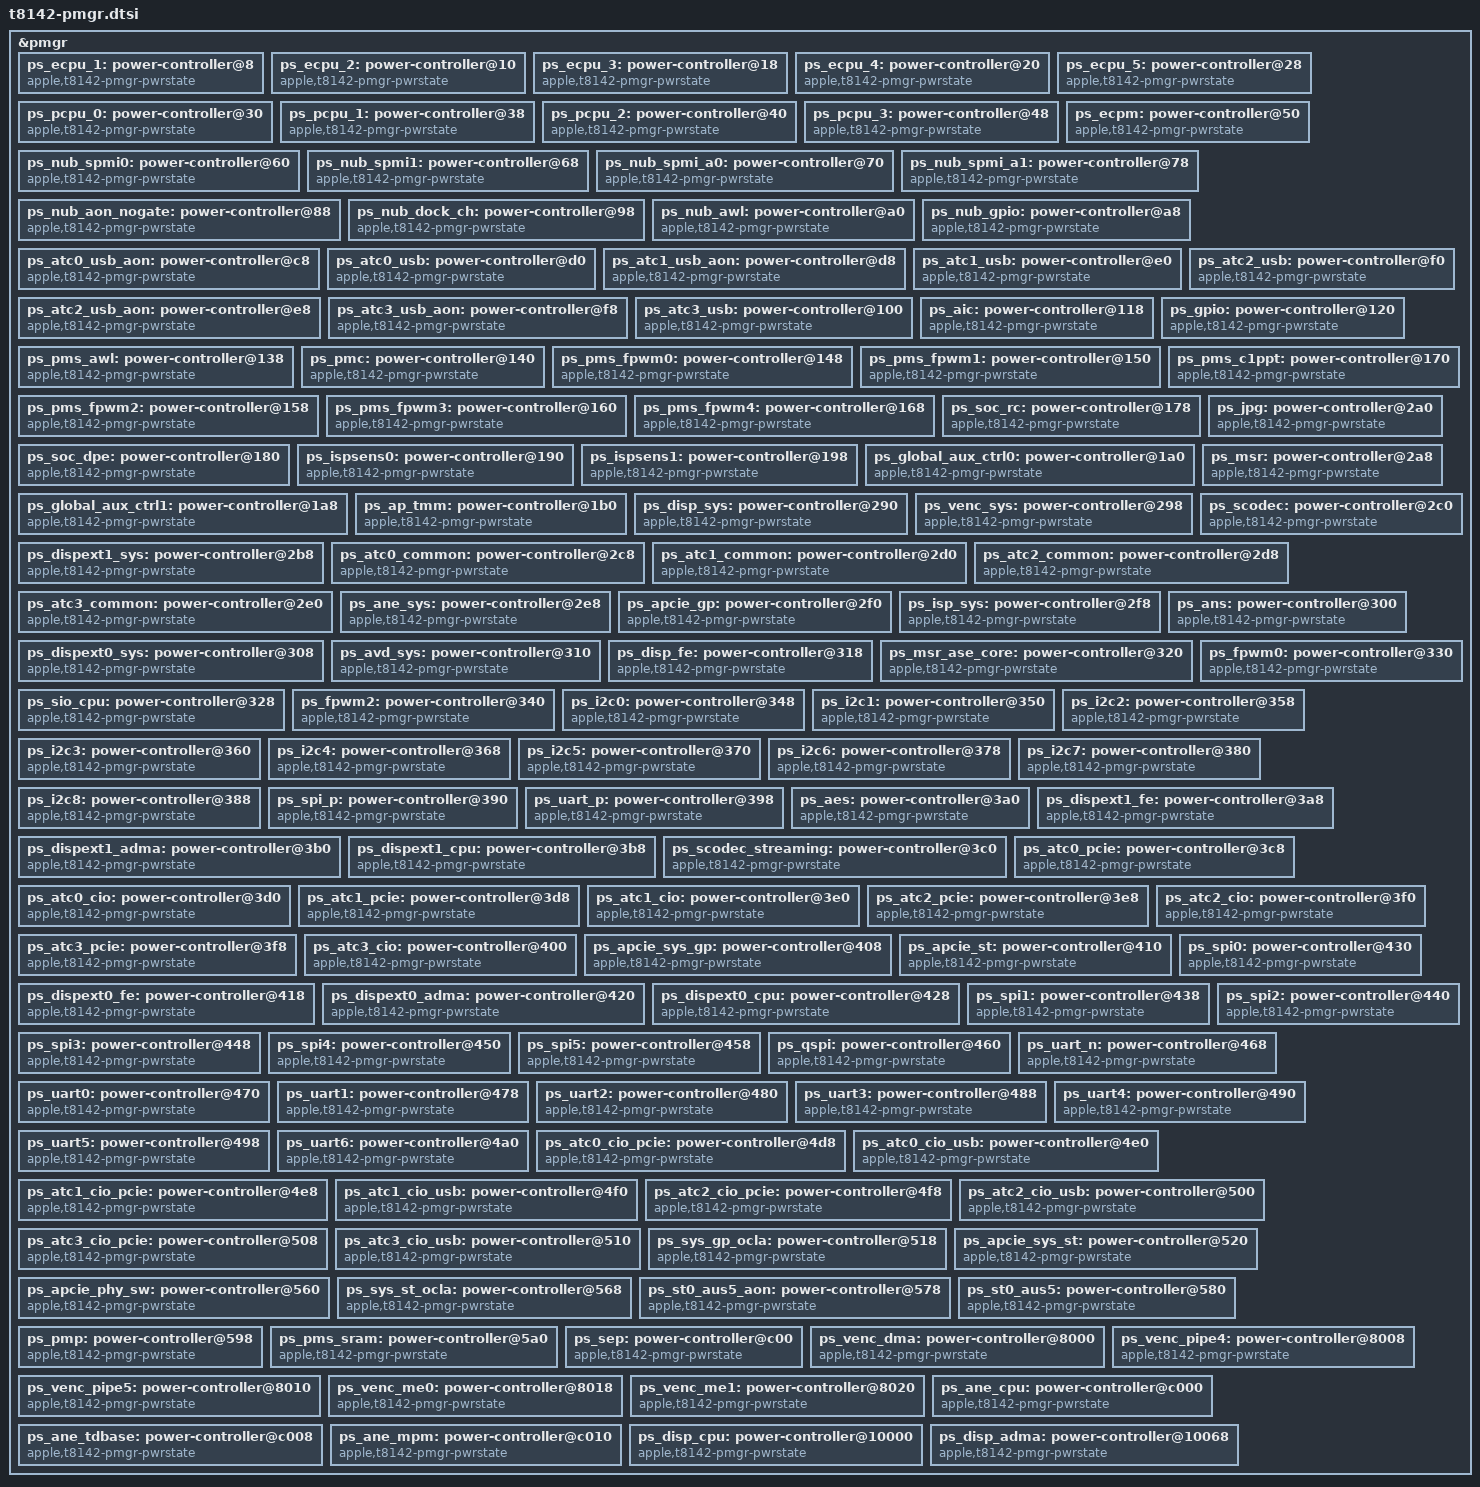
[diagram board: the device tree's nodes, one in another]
// SPDX-License-Identifier: GPL-2.0-or-later
/*
 * PMGR Power domains for the Apple T8142 "M5" SoC — 草稿
 *
 * ⚠️ 本文件是上游对应文件的**衍生作品**,依 GPL 保留署名:
 *     Copyright The Asahi Linux Contributors
 *     上游以 "GPL-2.0+ OR MIT" 发布;本文件选择 GPL-2.0-or-later
 *
 * 由 tools/pmgr_join.py 生成,输入:
 *   模板: t8132-pmgr.dtsi  (sha256 17c4fd5a7ec04af6)
 *       上游 AsahiLinux/linux, arch/arm64/boot/dts/apple/t8132-pmgr.dtsi
 *   数值: 本机 ADT 的 pmgr `devices` 属性(387 条)
 * 生成日期: 2026-10-11
 *
 * ⚠️ 草稿。必须人工校对 + 真机验证。见 docs/PMGR-DELTA.md。
 *
 * 记录 387 条:非虚拟 141 条,其中偏移唯一、写出为节点的 135 条。
 *
 * 地址结构:**绝对地址 = base(group) + offset**
 *   base 由 pmgr 的 ps-groups 表索引 reg 属性得到,本机三组分别是
 *   0x170700000 / 0x178280000 / 0x370e80000。
 *
 * 未写出的(6 条偏移仍不唯一 + 246 条虚拟域)见文件末尾两个注释块。
 */

/*
 * 🚨 本文件的 `reg` 是 pmgr **块内偏移**(来自 devices 的 offset 字段),
 *    配合 ps-groups 的 base 才构成绝对地址 —— 见 docs/PMGR-DEVICES.md。
 *    ⚠️ 且 pmgr 节点本身的地址在 t8142.dtsi 里是未翻译的子地址,注意。
 */

&pmgr {

	/* ⚠️ M4 模板里没有同名项 —— 下面属性是猜的,需确认 */
	ps_ecpu_1: power-controller@8 {
		compatible = "apple,t8142-pmgr-pwrstate", "apple,t8103-pmgr-pwrstate";
		reg = <0x8 4>;
		#power-domain-cells = <0>;
		#reset-cells = <0>;
		label = "ecpu_1";
	};

	/* ⚠️ M4 模板里没有同名项 —— 下面属性是猜的,需确认 */
	ps_ecpu_2: power-controller@10 {
		compatible = "apple,t8142-pmgr-pwrstate", "apple,t8103-pmgr-pwrstate";
		reg = <0x10 4>;
		#power-domain-cells = <0>;
		#reset-cells = <0>;
		label = "ecpu_2";
	};

	/* ⚠️ M4 模板里没有同名项 —— 下面属性是猜的,需确认 */
	ps_ecpu_3: power-controller@18 {
		compatible = "apple,t8142-pmgr-pwrstate", "apple,t8103-pmgr-pwrstate";
		reg = <0x18 4>;
		#power-domain-cells = <0>;
		#reset-cells = <0>;
		label = "ecpu_3";
	};

	/* ⚠️ M4 模板里没有同名项 —— 下面属性是猜的,需确认 */
	ps_ecpu_4: power-controller@20 {
		compatible = "apple,t8142-pmgr-pwrstate", "apple,t8103-pmgr-pwrstate";
		reg = <0x20 4>;
		#power-domain-cells = <0>;
		#reset-cells = <0>;
		label = "ecpu_4";
	};

	/* ⚠️ M4 模板里没有同名项 —— 下面属性是猜的,需确认 */
	ps_ecpu_5: power-controller@28 {
		compatible = "apple,t8142-pmgr-pwrstate", "apple,t8103-pmgr-pwrstate";
		reg = <0x28 4>;
		#power-domain-cells = <0>;
		#reset-cells = <0>;
		label = "ecpu_5";
	};

	/* ⚠️ M4 模板里没有同名项 —— 下面属性是猜的,需确认 */
	ps_pcpu_0: power-controller@30 {
		compatible = "apple,t8142-pmgr-pwrstate", "apple,t8103-pmgr-pwrstate";
		reg = <0x30 4>;
		#power-domain-cells = <0>;
		#reset-cells = <0>;
		label = "pcpu_0";
	};

	/* ⚠️ M4 模板里没有同名项 —— 下面属性是猜的,需确认 */
	ps_pcpu_1: power-controller@38 {
		compatible = "apple,t8142-pmgr-pwrstate", "apple,t8103-pmgr-pwrstate";
		reg = <0x38 4>;
		#power-domain-cells = <0>;
		#reset-cells = <0>;
		label = "pcpu_1";
	};

	/* ⚠️ M4 模板里没有同名项 —— 下面属性是猜的,需确认 */
	ps_pcpu_2: power-controller@40 {
		compatible = "apple,t8142-pmgr-pwrstate", "apple,t8103-pmgr-pwrstate";
		reg = <0x40 4>;
		#power-domain-cells = <0>;
		#reset-cells = <0>;
		label = "pcpu_2";
	};

	/* ⚠️ M4 模板里没有同名项 —— 下面属性是猜的,需确认 */
	ps_pcpu_3: power-controller@48 {
		compatible = "apple,t8142-pmgr-pwrstate", "apple,t8103-pmgr-pwrstate";
		reg = <0x48 4>;
		#power-domain-cells = <0>;
		#reset-cells = <0>;
		label = "pcpu_3";
	};

	/* ⚠️ M4 模板里没有同名项 —— 下面属性是猜的,需确认 */
	ps_ecpm: power-controller@50 {
		compatible = "apple,t8142-pmgr-pwrstate", "apple,t8103-pmgr-pwrstate";
		reg = <0x50 4>;
		#power-domain-cells = <0>;
		#reset-cells = <0>;
		label = "ecpm";
	};

	ps_nub_spmi0: power-controller@60 {
		compatible = "apple,t8142-pmgr-pwrstate", "apple,t8103-pmgr-pwrstate";
		reg = <0x60 4>;
		#power-domain-cells = <0>;
		#reset-cells = <0>;
		label = "nub_spmi0";  /* 结构抄自 M4 模板同名项 */
		apple,always-on; /* Core device */
	};

	ps_nub_spmi1: power-controller@68 {
		compatible = "apple,t8142-pmgr-pwrstate", "apple,t8103-pmgr-pwrstate";
		reg = <0x68 4>;
		#power-domain-cells = <0>;
		#reset-cells = <0>;
		label = "nub_spmi1";  /* 结构抄自 M4 模板同名项 */
		apple,always-on; /* Core device */
	};

	ps_nub_spmi_a0: power-controller@70 {
		compatible = "apple,t8142-pmgr-pwrstate", "apple,t8103-pmgr-pwrstate";
		reg = <0x70 4>;
		#power-domain-cells = <0>;
		#reset-cells = <0>;
		label = "nub_spmi_a0";  /* 结构抄自 M4 模板同名项 */
		apple,always-on; /* Core device */
	};

	ps_nub_spmi_a1: power-controller@78 {
		compatible = "apple,t8142-pmgr-pwrstate", "apple,t8103-pmgr-pwrstate";
		reg = <0x78 4>;
		#power-domain-cells = <0>;
		#reset-cells = <0>;
		label = "nub_spmi_a1";  /* 结构抄自 M4 模板同名项 */
		apple,always-on; /* Core device */
	};

	/* ⚠️ M4 模板里没有同名项 —— 下面属性是猜的,需确认 */
	ps_nub_aon_nogate: power-controller@88 {
		compatible = "apple,t8142-pmgr-pwrstate", "apple,t8103-pmgr-pwrstate";
		reg = <0x88 4>;
		#power-domain-cells = <0>;
		#reset-cells = <0>;
		label = "nub_aon_nogate";
	};

	/* ⚠️ M4 模板里没有同名项 —— 下面属性是猜的,需确认 */
	ps_nub_dock_ch: power-controller@98 {
		compatible = "apple,t8142-pmgr-pwrstate", "apple,t8103-pmgr-pwrstate";
		reg = <0x98 4>;
		#power-domain-cells = <0>;
		#reset-cells = <0>;
		label = "nub_dock_ch";
	};

	/* ⚠️ M4 模板里没有同名项 —— 下面属性是猜的,需确认 */
	ps_nub_awl: power-controller@a0 {
		compatible = "apple,t8142-pmgr-pwrstate", "apple,t8103-pmgr-pwrstate";
		reg = <0xa0 4>;
		#power-domain-cells = <0>;
		#reset-cells = <0>;
		label = "nub_awl";
	};

	ps_nub_gpio: power-controller@a8 {
		compatible = "apple,t8142-pmgr-pwrstate", "apple,t8103-pmgr-pwrstate";
		reg = <0xa8 4>;
		#power-domain-cells = <0>;
		#reset-cells = <0>;
		label = "nub_gpio";  /* 结构抄自 M4 模板同名项 */
		apple,always-on; /* Core device */
	};

	ps_atc0_usb_aon: power-controller@c8 {
		compatible = "apple,t8142-pmgr-pwrstate", "apple,t8103-pmgr-pwrstate";
		reg = <0xc8 4>;
		#power-domain-cells = <0>;
		#reset-cells = <0>;
		label = "atc0_usb_aon";  /* 结构抄自 M4 模板同名项 */
	};

	ps_atc0_usb: power-controller@d0 {
		compatible = "apple,t8142-pmgr-pwrstate", "apple,t8103-pmgr-pwrstate";
		reg = <0xd0 4>;
		#power-domain-cells = <0>;
		#reset-cells = <0>;
		label = "atc0_usb";  /* 结构抄自 M4 模板同名项 */
	};

	ps_atc1_usb_aon: power-controller@d8 {
		compatible = "apple,t8142-pmgr-pwrstate", "apple,t8103-pmgr-pwrstate";
		reg = <0xd8 4>;
		#power-domain-cells = <0>;
		#reset-cells = <0>;
		label = "atc1_usb_aon";  /* 结构抄自 M4 模板同名项 */
	};

	ps_atc1_usb: power-controller@e0 {
		compatible = "apple,t8142-pmgr-pwrstate", "apple,t8103-pmgr-pwrstate";
		reg = <0xe0 4>;
		#power-domain-cells = <0>;
		#reset-cells = <0>;
		label = "atc1_usb";  /* 结构抄自 M4 模板同名项 */
	};

	ps_atc2_usb_aon: power-controller@e8 {
		compatible = "apple,t8142-pmgr-pwrstate", "apple,t8103-pmgr-pwrstate";
		reg = <0xe8 4>;
		#power-domain-cells = <0>;
		#reset-cells = <0>;
		label = "atc2_usb_aon";  /* 结构抄自 M4 模板同名项 */
	};

	ps_atc2_usb: power-controller@f0 {
		compatible = "apple,t8142-pmgr-pwrstate", "apple,t8103-pmgr-pwrstate";
		reg = <0xf0 4>;
		#power-domain-cells = <0>;
		#reset-cells = <0>;
		label = "atc2_usb";  /* 结构抄自 M4 模板同名项 */
	};

	ps_atc3_usb_aon: power-controller@f8 {
		compatible = "apple,t8142-pmgr-pwrstate", "apple,t8103-pmgr-pwrstate";
		reg = <0xf8 4>;
		#power-domain-cells = <0>;
		#reset-cells = <0>;
		label = "atc3_usb_aon";  /* 结构抄自 M4 模板同名项 */
	};

	ps_atc3_usb: power-controller@100 {
		compatible = "apple,t8142-pmgr-pwrstate", "apple,t8103-pmgr-pwrstate";
		reg = <0x100 4>;
		#power-domain-cells = <0>;
		#reset-cells = <0>;
		label = "atc3_usb";  /* 结构抄自 M4 模板同名项 */
	};

	ps_aic: power-controller@118 {
		compatible = "apple,t8142-pmgr-pwrstate", "apple,t8103-pmgr-pwrstate";
		reg = <0x118 4>;
		#power-domain-cells = <0>;
		#reset-cells = <0>;
		label = "aic";  /* 结构抄自 M4 模板同名项 */
		apple,always-on; /* Core device */
	};

	ps_gpio: power-controller@120 {
		compatible = "apple,t8142-pmgr-pwrstate", "apple,t8103-pmgr-pwrstate";
		reg = <0x120 4>;
		#power-domain-cells = <0>;
		#reset-cells = <0>;
		label = "gpio";  /* 结构抄自 M4 模板同名项 */
	};

	/* ⚠️ M4 模板里没有同名项 —— 下面属性是猜的,需确认 */
	ps_pms_awl: power-controller@138 {
		compatible = "apple,t8142-pmgr-pwrstate", "apple,t8103-pmgr-pwrstate";
		reg = <0x138 4>;
		#power-domain-cells = <0>;
		#reset-cells = <0>;
		label = "pms_awl";
	};

	ps_pmc: power-controller@140 {
		compatible = "apple,t8142-pmgr-pwrstate", "apple,t8103-pmgr-pwrstate";
		reg = <0x140 4>;
		#power-domain-cells = <0>;
		#reset-cells = <0>;
		label = "pmc";  /* 结构抄自 M4 模板同名项 */
	};

	ps_pms_fpwm0: power-controller@148 {
		compatible = "apple,t8142-pmgr-pwrstate", "apple,t8103-pmgr-pwrstate";
		reg = <0x148 4>;
		#power-domain-cells = <0>;
		#reset-cells = <0>;
		label = "pms_fpwm0";  /* 结构抄自 M4 模板同名项 */
	};

	ps_pms_fpwm1: power-controller@150 {
		compatible = "apple,t8142-pmgr-pwrstate", "apple,t8103-pmgr-pwrstate";
		reg = <0x150 4>;
		#power-domain-cells = <0>;
		#reset-cells = <0>;
		label = "pms_fpwm1";  /* 结构抄自 M4 模板同名项 */
	};

	ps_pms_fpwm2: power-controller@158 {
		compatible = "apple,t8142-pmgr-pwrstate", "apple,t8103-pmgr-pwrstate";
		reg = <0x158 4>;
		#power-domain-cells = <0>;
		#reset-cells = <0>;
		label = "pms_fpwm2";  /* 结构抄自 M4 模板同名项 */
	};

	ps_pms_fpwm3: power-controller@160 {
		compatible = "apple,t8142-pmgr-pwrstate", "apple,t8103-pmgr-pwrstate";
		reg = <0x160 4>;
		#power-domain-cells = <0>;
		#reset-cells = <0>;
		label = "pms_fpwm3";  /* 结构抄自 M4 模板同名项 */
	};

	ps_pms_fpwm4: power-controller@168 {
		compatible = "apple,t8142-pmgr-pwrstate", "apple,t8103-pmgr-pwrstate";
		reg = <0x168 4>;
		#power-domain-cells = <0>;
		#reset-cells = <0>;
		label = "pms_fpwm4";  /* 结构抄自 M4 模板同名项 */
	};

	ps_pms_c1ppt: power-controller@170 {
		compatible = "apple,t8142-pmgr-pwrstate", "apple,t8103-pmgr-pwrstate";
		reg = <0x170 4>;
		#power-domain-cells = <0>;
		#reset-cells = <0>;
		label = "pms_c1ppt";  /* 结构抄自 M4 模板同名项 */
	};

	ps_soc_rc: power-controller@178 {
		compatible = "apple,t8142-pmgr-pwrstate", "apple,t8103-pmgr-pwrstate";
		reg = <0x178 4>;
		#power-domain-cells = <0>;
		#reset-cells = <0>;
		label = "soc_rc";  /* 结构抄自 M4 模板同名项 */
	};

	ps_soc_dpe: power-controller@180 {
		compatible = "apple,t8142-pmgr-pwrstate", "apple,t8103-pmgr-pwrstate";
		reg = <0x180 4>;
		#power-domain-cells = <0>;
		#reset-cells = <0>;
		label = "soc_dpe";  /* 结构抄自 M4 模板同名项 */
		apple,always-on; /* Core device */
	};

	/* ⚠️ M4 模板里没有同名项 —— 下面属性是猜的,需确认 */
	ps_ispsens0: power-controller@190 {
		compatible = "apple,t8142-pmgr-pwrstate", "apple,t8103-pmgr-pwrstate";
		reg = <0x190 4>;
		#power-domain-cells = <0>;
		#reset-cells = <0>;
		label = "ispsens0";
	};

	/* ⚠️ M4 模板里没有同名项 —— 下面属性是猜的,需确认 */
	ps_ispsens1: power-controller@198 {
		compatible = "apple,t8142-pmgr-pwrstate", "apple,t8103-pmgr-pwrstate";
		reg = <0x198 4>;
		#power-domain-cells = <0>;
		#reset-cells = <0>;
		label = "ispsens1";
	};

	/* ⚠️ M4 模板里没有同名项 —— 下面属性是猜的,需确认 */
	ps_global_aux_ctrl0: power-controller@1a0 {
		compatible = "apple,t8142-pmgr-pwrstate", "apple,t8103-pmgr-pwrstate";
		reg = <0x1a0 4>;
		#power-domain-cells = <0>;
		#reset-cells = <0>;
		label = "global_aux_ctrl0";
	};

	/* ⚠️ M4 模板里没有同名项 —— 下面属性是猜的,需确认 */
	ps_global_aux_ctrl1: power-controller@1a8 {
		compatible = "apple,t8142-pmgr-pwrstate", "apple,t8103-pmgr-pwrstate";
		reg = <0x1a8 4>;
		#power-domain-cells = <0>;
		#reset-cells = <0>;
		label = "global_aux_ctrl1";
	};

	ps_ap_tmm: power-controller@1b0 {
		compatible = "apple,t8142-pmgr-pwrstate", "apple,t8103-pmgr-pwrstate";
		reg = <0x1b0 4>;
		#power-domain-cells = <0>;
		#reset-cells = <0>;
		label = "ap_tmm";  /* 结构抄自 M4 模板同名项 */
	};

	ps_disp_sys: power-controller@290 {
		compatible = "apple,t8142-pmgr-pwrstate", "apple,t8103-pmgr-pwrstate";
		reg = <0x290 4>;
		#power-domain-cells = <0>;
		#reset-cells = <0>;
		label = "disp_sys";  /* 结构抄自 M4 模板同名项 */
		apple,always-on; /* Core device */
	};

	ps_venc_sys: power-controller@298 {
		compatible = "apple,t8142-pmgr-pwrstate", "apple,t8103-pmgr-pwrstate";
		reg = <0x298 4>;
		#power-domain-cells = <0>;
		#reset-cells = <0>;
		label = "venc_sys";  /* 结构抄自 M4 模板同名项 */
	};

	ps_jpg: power-controller@2a0 {
		compatible = "apple,t8142-pmgr-pwrstate", "apple,t8103-pmgr-pwrstate";
		reg = <0x2a0 4>;
		#power-domain-cells = <0>;
		#reset-cells = <0>;
		label = "jpg";  /* 结构抄自 M4 模板同名项 */
	};

	ps_msr: power-controller@2a8 {
		compatible = "apple,t8142-pmgr-pwrstate", "apple,t8103-pmgr-pwrstate";
		reg = <0x2a8 4>;
		#power-domain-cells = <0>;
		#reset-cells = <0>;
		label = "msr";  /* 结构抄自 M4 模板同名项 */
	};

	ps_dispext1_sys: power-controller@2b8 {
		compatible = "apple,t8142-pmgr-pwrstate", "apple,t8103-pmgr-pwrstate";
		reg = <0x2b8 4>;
		#power-domain-cells = <0>;
		#reset-cells = <0>;
		label = "dispext1_sys";  /* 结构抄自 M4 模板同名项 */
	};

	ps_scodec: power-controller@2c0 {
		compatible = "apple,t8142-pmgr-pwrstate", "apple,t8103-pmgr-pwrstate";
		reg = <0x2c0 4>;
		#power-domain-cells = <0>;
		#reset-cells = <0>;
		label = "scodec";  /* 结构抄自 M4 模板同名项 */
	};

	ps_atc0_common: power-controller@2c8 {
		compatible = "apple,t8142-pmgr-pwrstate", "apple,t8103-pmgr-pwrstate";
		reg = <0x2c8 4>;
		#power-domain-cells = <0>;
		#reset-cells = <0>;
		label = "atc0_common";  /* 结构抄自 M4 模板同名项 */
	};

	ps_atc1_common: power-controller@2d0 {
		compatible = "apple,t8142-pmgr-pwrstate", "apple,t8103-pmgr-pwrstate";
		reg = <0x2d0 4>;
		#power-domain-cells = <0>;
		#reset-cells = <0>;
		label = "atc1_common";  /* 结构抄自 M4 模板同名项 */
	};

	ps_atc2_common: power-controller@2d8 {
		compatible = "apple,t8142-pmgr-pwrstate", "apple,t8103-pmgr-pwrstate";
		reg = <0x2d8 4>;
		#power-domain-cells = <0>;
		#reset-cells = <0>;
		label = "atc2_common";  /* 结构抄自 M4 模板同名项 */
	};

	ps_atc3_common: power-controller@2e0 {
		compatible = "apple,t8142-pmgr-pwrstate", "apple,t8103-pmgr-pwrstate";
		reg = <0x2e0 4>;
		#power-domain-cells = <0>;
		#reset-cells = <0>;
		label = "atc3_common";  /* 结构抄自 M4 模板同名项 */
	};

	ps_ane_sys: power-controller@2e8 {
		compatible = "apple,t8142-pmgr-pwrstate", "apple,t8103-pmgr-pwrstate";
		reg = <0x2e8 4>;
		#power-domain-cells = <0>;
		#reset-cells = <0>;
		label = "ane_sys";  /* 结构抄自 M4 模板同名项 */
	};

	ps_apcie_gp: power-controller@2f0 {
		compatible = "apple,t8142-pmgr-pwrstate", "apple,t8103-pmgr-pwrstate";
		reg = <0x2f0 4>;
		#power-domain-cells = <0>;
		#reset-cells = <0>;
		label = "apcie_gp";  /* 结构抄自 M4 模板同名项 */
	};

	/* ⚠️ M4 模板里没有同名项 —— 下面属性是猜的,需确认 */
	ps_isp_sys: power-controller@2f8 {
		compatible = "apple,t8142-pmgr-pwrstate", "apple,t8103-pmgr-pwrstate";
		reg = <0x2f8 4>;
		#power-domain-cells = <0>;
		#reset-cells = <0>;
		label = "isp_sys";
	};

	ps_ans: power-controller@300 {
		compatible = "apple,t8142-pmgr-pwrstate", "apple,t8103-pmgr-pwrstate";
		reg = <0x300 4>;
		#power-domain-cells = <0>;
		#reset-cells = <0>;
		label = "ans";  /* 结构抄自 M4 模板同名项 */
	};

	ps_dispext0_sys: power-controller@308 {
		compatible = "apple,t8142-pmgr-pwrstate", "apple,t8103-pmgr-pwrstate";
		reg = <0x308 4>;
		#power-domain-cells = <0>;
		#reset-cells = <0>;
		label = "dispext0_sys";  /* 结构抄自 M4 模板同名项 */
	};

	ps_avd_sys: power-controller@310 {
		compatible = "apple,t8142-pmgr-pwrstate", "apple,t8103-pmgr-pwrstate";
		reg = <0x310 4>;
		#power-domain-cells = <0>;
		#reset-cells = <0>;
		label = "avd_sys";  /* 结构抄自 M4 模板同名项 */
	};

	ps_disp_fe: power-controller@318 {
		compatible = "apple,t8142-pmgr-pwrstate", "apple,t8103-pmgr-pwrstate";
		reg = <0x318 4>;
		#power-domain-cells = <0>;
		#reset-cells = <0>;
		label = "disp_fe";  /* 结构抄自 M4 模板同名项 */
		apple,always-on; /* Core device */
	};

	ps_msr_ase_core: power-controller@320 {
		compatible = "apple,t8142-pmgr-pwrstate", "apple,t8103-pmgr-pwrstate";
		reg = <0x320 4>;
		#power-domain-cells = <0>;
		#reset-cells = <0>;
		label = "msr_ase_core";  /* 结构抄自 M4 模板同名项 */
	};

	ps_sio_cpu: power-controller@328 {
		compatible = "apple,t8142-pmgr-pwrstate", "apple,t8103-pmgr-pwrstate";
		reg = <0x328 4>;
		#power-domain-cells = <0>;
		#reset-cells = <0>;
		label = "sio_cpu";  /* 结构抄自 M4 模板同名项 */
	};

	ps_fpwm0: power-controller@330 {
		compatible = "apple,t8142-pmgr-pwrstate", "apple,t8103-pmgr-pwrstate";
		reg = <0x330 4>;
		#power-domain-cells = <0>;
		#reset-cells = <0>;
		label = "fpwm0";  /* 结构抄自 M4 模板同名项 */
	};

	ps_fpwm2: power-controller@340 {
		compatible = "apple,t8142-pmgr-pwrstate", "apple,t8103-pmgr-pwrstate";
		reg = <0x340 4>;
		#power-domain-cells = <0>;
		#reset-cells = <0>;
		label = "fpwm2";  /* 结构抄自 M4 模板同名项 */
	};

	ps_i2c0: power-controller@348 {
		compatible = "apple,t8142-pmgr-pwrstate", "apple,t8103-pmgr-pwrstate";
		reg = <0x348 4>;
		#power-domain-cells = <0>;
		#reset-cells = <0>;
		label = "i2c0";  /* 结构抄自 M4 模板同名项 */
	};

	ps_i2c1: power-controller@350 {
		compatible = "apple,t8142-pmgr-pwrstate", "apple,t8103-pmgr-pwrstate";
		reg = <0x350 4>;
		#power-domain-cells = <0>;
		#reset-cells = <0>;
		label = "i2c1";  /* 结构抄自 M4 模板同名项 */
	};

	ps_i2c2: power-controller@358 {
		compatible = "apple,t8142-pmgr-pwrstate", "apple,t8103-pmgr-pwrstate";
		reg = <0x358 4>;
		#power-domain-cells = <0>;
		#reset-cells = <0>;
		label = "i2c2";  /* 结构抄自 M4 模板同名项 */
	};

	ps_i2c3: power-controller@360 {
		compatible = "apple,t8142-pmgr-pwrstate", "apple,t8103-pmgr-pwrstate";
		reg = <0x360 4>;
		#power-domain-cells = <0>;
		#reset-cells = <0>;
		label = "i2c3";  /* 结构抄自 M4 模板同名项 */
	};

	ps_i2c4: power-controller@368 {
		compatible = "apple,t8142-pmgr-pwrstate", "apple,t8103-pmgr-pwrstate";
		reg = <0x368 4>;
		#power-domain-cells = <0>;
		#reset-cells = <0>;
		label = "i2c4";  /* 结构抄自 M4 模板同名项 */
	};

	ps_i2c5: power-controller@370 {
		compatible = "apple,t8142-pmgr-pwrstate", "apple,t8103-pmgr-pwrstate";
		reg = <0x370 4>;
		#power-domain-cells = <0>;
		#reset-cells = <0>;
		label = "i2c5";  /* 结构抄自 M4 模板同名项 */
	};

	ps_i2c6: power-controller@378 {
		compatible = "apple,t8142-pmgr-pwrstate", "apple,t8103-pmgr-pwrstate";
		reg = <0x378 4>;
		#power-domain-cells = <0>;
		#reset-cells = <0>;
		label = "i2c6";  /* 结构抄自 M4 模板同名项 */
	};

	ps_i2c7: power-controller@380 {
		compatible = "apple,t8142-pmgr-pwrstate", "apple,t8103-pmgr-pwrstate";
		reg = <0x380 4>;
		#power-domain-cells = <0>;
		#reset-cells = <0>;
		label = "i2c7";  /* 结构抄自 M4 模板同名项 */
	};

	ps_i2c8: power-controller@388 {
		compatible = "apple,t8142-pmgr-pwrstate", "apple,t8103-pmgr-pwrstate";
		reg = <0x388 4>;
		#power-domain-cells = <0>;
		#reset-cells = <0>;
		label = "i2c8";  /* 结构抄自 M4 模板同名项 */
	};

	ps_spi_p: power-controller@390 {
		compatible = "apple,t8142-pmgr-pwrstate", "apple,t8103-pmgr-pwrstate";
		reg = <0x390 4>;
		#power-domain-cells = <0>;
		#reset-cells = <0>;
		label = "spi_p";  /* 结构抄自 M4 模板同名项 */
		apple,always-on; /* Core device */
	};

	ps_uart_p: power-controller@398 {
		compatible = "apple,t8142-pmgr-pwrstate", "apple,t8103-pmgr-pwrstate";
		reg = <0x398 4>;
		#power-domain-cells = <0>;
		#reset-cells = <0>;
		label = "uart_p";  /* 结构抄自 M4 模板同名项 */
		apple,always-on; /* Core device */
	};

	ps_aes: power-controller@3a0 {
		compatible = "apple,t8142-pmgr-pwrstate", "apple,t8103-pmgr-pwrstate";
		reg = <0x3a0 4>;
		#power-domain-cells = <0>;
		#reset-cells = <0>;
		label = "aes";  /* 结构抄自 M4 模板同名项 */
	};

	ps_dispext1_fe: power-controller@3a8 {
		compatible = "apple,t8142-pmgr-pwrstate", "apple,t8103-pmgr-pwrstate";
		reg = <0x3a8 4>;
		#power-domain-cells = <0>;
		#reset-cells = <0>;
		label = "dispext1_fe";  /* 结构抄自 M4 模板同名项 */
	};

	/* ⚠️ M4 模板里没有同名项 —— 下面属性是猜的,需确认 */
	ps_dispext1_adma: power-controller@3b0 {
		compatible = "apple,t8142-pmgr-pwrstate", "apple,t8103-pmgr-pwrstate";
		reg = <0x3b0 4>;
		#power-domain-cells = <0>;
		#reset-cells = <0>;
		label = "dispext1_adma";
	};

	ps_dispext1_cpu: power-controller@3b8 {
		compatible = "apple,t8142-pmgr-pwrstate", "apple,t8103-pmgr-pwrstate";
		reg = <0x3b8 4>;
		#power-domain-cells = <0>;
		#reset-cells = <0>;
		label = "dispext1_cpu";  /* 结构抄自 M4 模板同名项 */
	};

	ps_scodec_streaming: power-controller@3c0 {
		compatible = "apple,t8142-pmgr-pwrstate", "apple,t8103-pmgr-pwrstate";
		reg = <0x3c0 4>;
		#power-domain-cells = <0>;
		#reset-cells = <0>;
		label = "scodec_streaming";  /* 结构抄自 M4 模板同名项 */
	};

	ps_atc0_pcie: power-controller@3c8 {
		compatible = "apple,t8142-pmgr-pwrstate", "apple,t8103-pmgr-pwrstate";
		reg = <0x3c8 4>;
		#power-domain-cells = <0>;
		#reset-cells = <0>;
		label = "atc0_pcie";  /* 结构抄自 M4 模板同名项 */
	};

	ps_atc0_cio: power-controller@3d0 {
		compatible = "apple,t8142-pmgr-pwrstate", "apple,t8103-pmgr-pwrstate";
		reg = <0x3d0 4>;
		#power-domain-cells = <0>;
		#reset-cells = <0>;
		label = "atc0_cio";  /* 结构抄自 M4 模板同名项 */
	};

	ps_atc1_pcie: power-controller@3d8 {
		compatible = "apple,t8142-pmgr-pwrstate", "apple,t8103-pmgr-pwrstate";
		reg = <0x3d8 4>;
		#power-domain-cells = <0>;
		#reset-cells = <0>;
		label = "atc1_pcie";  /* 结构抄自 M4 模板同名项 */
	};

	ps_atc1_cio: power-controller@3e0 {
		compatible = "apple,t8142-pmgr-pwrstate", "apple,t8103-pmgr-pwrstate";
		reg = <0x3e0 4>;
		#power-domain-cells = <0>;
		#reset-cells = <0>;
		label = "atc1_cio";  /* 结构抄自 M4 模板同名项 */
	};

	ps_atc2_pcie: power-controller@3e8 {
		compatible = "apple,t8142-pmgr-pwrstate", "apple,t8103-pmgr-pwrstate";
		reg = <0x3e8 4>;
		#power-domain-cells = <0>;
		#reset-cells = <0>;
		label = "atc2_pcie";  /* 结构抄自 M4 模板同名项 */
	};

	ps_atc2_cio: power-controller@3f0 {
		compatible = "apple,t8142-pmgr-pwrstate", "apple,t8103-pmgr-pwrstate";
		reg = <0x3f0 4>;
		#power-domain-cells = <0>;
		#reset-cells = <0>;
		label = "atc2_cio";  /* 结构抄自 M4 模板同名项 */
	};

	ps_atc3_pcie: power-controller@3f8 {
		compatible = "apple,t8142-pmgr-pwrstate", "apple,t8103-pmgr-pwrstate";
		reg = <0x3f8 4>;
		#power-domain-cells = <0>;
		#reset-cells = <0>;
		label = "atc3_pcie";  /* 结构抄自 M4 模板同名项 */
	};

	ps_atc3_cio: power-controller@400 {
		compatible = "apple,t8142-pmgr-pwrstate", "apple,t8103-pmgr-pwrstate";
		reg = <0x400 4>;
		#power-domain-cells = <0>;
		#reset-cells = <0>;
		label = "atc3_cio";  /* 结构抄自 M4 模板同名项 */
	};

	ps_apcie_sys_gp: power-controller@408 {
		compatible = "apple,t8142-pmgr-pwrstate", "apple,t8103-pmgr-pwrstate";
		reg = <0x408 4>;
		#power-domain-cells = <0>;
		#reset-cells = <0>;
		label = "apcie_sys_gp";  /* 结构抄自 M4 模板同名项 */
	};

	ps_apcie_st: power-controller@410 {
		compatible = "apple,t8142-pmgr-pwrstate", "apple,t8103-pmgr-pwrstate";
		reg = <0x410 4>;
		#power-domain-cells = <0>;
		#reset-cells = <0>;
		label = "apcie_st";  /* 结构抄自 M4 模板同名项 */
	};

	ps_dispext0_fe: power-controller@418 {
		compatible = "apple,t8142-pmgr-pwrstate", "apple,t8103-pmgr-pwrstate";
		reg = <0x418 4>;
		#power-domain-cells = <0>;
		#reset-cells = <0>;
		label = "dispext0_fe";  /* 结构抄自 M4 模板同名项 */
	};

	/* ⚠️ M4 模板里没有同名项 —— 下面属性是猜的,需确认 */
	ps_dispext0_adma: power-controller@420 {
		compatible = "apple,t8142-pmgr-pwrstate", "apple,t8103-pmgr-pwrstate";
		reg = <0x420 4>;
		#power-domain-cells = <0>;
		#reset-cells = <0>;
		label = "dispext0_adma";
	};

	ps_dispext0_cpu: power-controller@428 {
		compatible = "apple,t8142-pmgr-pwrstate", "apple,t8103-pmgr-pwrstate";
		reg = <0x428 4>;
		#power-domain-cells = <0>;
		#reset-cells = <0>;
		label = "dispext0_cpu";  /* 结构抄自 M4 模板同名项 */
	};

	ps_spi0: power-controller@430 {
		compatible = "apple,t8142-pmgr-pwrstate", "apple,t8103-pmgr-pwrstate";
		reg = <0x430 4>;
		#power-domain-cells = <0>;
		#reset-cells = <0>;
		label = "spi0";  /* 结构抄自 M4 模板同名项 */
	};

	ps_spi1: power-controller@438 {
		compatible = "apple,t8142-pmgr-pwrstate", "apple,t8103-pmgr-pwrstate";
		reg = <0x438 4>;
		#power-domain-cells = <0>;
		#reset-cells = <0>;
		label = "spi1";  /* 结构抄自 M4 模板同名项 */
	};

	ps_spi2: power-controller@440 {
		compatible = "apple,t8142-pmgr-pwrstate", "apple,t8103-pmgr-pwrstate";
		reg = <0x440 4>;
		#power-domain-cells = <0>;
		#reset-cells = <0>;
		label = "spi2";  /* 结构抄自 M4 模板同名项 */
	};

	ps_spi3: power-controller@448 {
		compatible = "apple,t8142-pmgr-pwrstate", "apple,t8103-pmgr-pwrstate";
		reg = <0x448 4>;
		#power-domain-cells = <0>;
		#reset-cells = <0>;
		label = "spi3";  /* 结构抄自 M4 模板同名项 */
	};

	ps_spi4: power-controller@450 {
		compatible = "apple,t8142-pmgr-pwrstate", "apple,t8103-pmgr-pwrstate";
		reg = <0x450 4>;
		#power-domain-cells = <0>;
		#reset-cells = <0>;
		label = "spi4";  /* 结构抄自 M4 模板同名项 */
	};

	ps_spi5: power-controller@458 {
		compatible = "apple,t8142-pmgr-pwrstate", "apple,t8103-pmgr-pwrstate";
		reg = <0x458 4>;
		#power-domain-cells = <0>;
		#reset-cells = <0>;
		label = "spi5";  /* 结构抄自 M4 模板同名项 */
	};

	ps_qspi: power-controller@460 {
		compatible = "apple,t8142-pmgr-pwrstate", "apple,t8103-pmgr-pwrstate";
		reg = <0x460 4>;
		#power-domain-cells = <0>;
		#reset-cells = <0>;
		label = "qspi";  /* 结构抄自 M4 模板同名项 */
	};

	ps_uart_n: power-controller@468 {
		compatible = "apple,t8142-pmgr-pwrstate", "apple,t8103-pmgr-pwrstate";
		reg = <0x468 4>;
		#power-domain-cells = <0>;
		#reset-cells = <0>;
		label = "uart_n";  /* 结构抄自 M4 模板同名项 */
	};

	ps_uart0: power-controller@470 {
		compatible = "apple,t8142-pmgr-pwrstate", "apple,t8103-pmgr-pwrstate";
		reg = <0x470 4>;
		#power-domain-cells = <0>;
		#reset-cells = <0>;
		label = "uart0";  /* 结构抄自 M4 模板同名项 */
	};

	ps_uart1: power-controller@478 {
		compatible = "apple,t8142-pmgr-pwrstate", "apple,t8103-pmgr-pwrstate";
		reg = <0x478 4>;
		#power-domain-cells = <0>;
		#reset-cells = <0>;
		label = "uart1";  /* 结构抄自 M4 模板同名项 */
	};

	ps_uart2: power-controller@480 {
		compatible = "apple,t8142-pmgr-pwrstate", "apple,t8103-pmgr-pwrstate";
		reg = <0x480 4>;
		#power-domain-cells = <0>;
		#reset-cells = <0>;
		label = "uart2";  /* 结构抄自 M4 模板同名项 */
	};

	ps_uart3: power-controller@488 {
		compatible = "apple,t8142-pmgr-pwrstate", "apple,t8103-pmgr-pwrstate";
		reg = <0x488 4>;
		#power-domain-cells = <0>;
		#reset-cells = <0>;
		label = "uart3";  /* 结构抄自 M4 模板同名项 */
	};

	ps_uart4: power-controller@490 {
		compatible = "apple,t8142-pmgr-pwrstate", "apple,t8103-pmgr-pwrstate";
		reg = <0x490 4>;
		#power-domain-cells = <0>;
		#reset-cells = <0>;
		label = "uart4";  /* 结构抄自 M4 模板同名项 */
	};

	ps_uart5: power-controller@498 {
		compatible = "apple,t8142-pmgr-pwrstate", "apple,t8103-pmgr-pwrstate";
		reg = <0x498 4>;
		#power-domain-cells = <0>;
		#reset-cells = <0>;
		label = "uart5";  /* 结构抄自 M4 模板同名项 */
	};

	ps_uart6: power-controller@4a0 {
		compatible = "apple,t8142-pmgr-pwrstate", "apple,t8103-pmgr-pwrstate";
		reg = <0x4a0 4>;
		#power-domain-cells = <0>;
		#reset-cells = <0>;
		label = "uart6";  /* 结构抄自 M4 模板同名项 */
	};

	ps_atc0_cio_pcie: power-controller@4d8 {
		compatible = "apple,t8142-pmgr-pwrstate", "apple,t8103-pmgr-pwrstate";
		reg = <0x4d8 4>;
		#power-domain-cells = <0>;
		#reset-cells = <0>;
		label = "atc0_cio_pcie";  /* 结构抄自 M4 模板同名项 */
	};

	ps_atc0_cio_usb: power-controller@4e0 {
		compatible = "apple,t8142-pmgr-pwrstate", "apple,t8103-pmgr-pwrstate";
		reg = <0x4e0 4>;
		#power-domain-cells = <0>;
		#reset-cells = <0>;
		label = "atc0_cio_usb";  /* 结构抄自 M4 模板同名项 */
	};

	ps_atc1_cio_pcie: power-controller@4e8 {
		compatible = "apple,t8142-pmgr-pwrstate", "apple,t8103-pmgr-pwrstate";
		reg = <0x4e8 4>;
		#power-domain-cells = <0>;
		#reset-cells = <0>;
		label = "atc1_cio_pcie";  /* 结构抄自 M4 模板同名项 */
	};

	ps_atc1_cio_usb: power-controller@4f0 {
		compatible = "apple,t8142-pmgr-pwrstate", "apple,t8103-pmgr-pwrstate";
		reg = <0x4f0 4>;
		#power-domain-cells = <0>;
		#reset-cells = <0>;
		label = "atc1_cio_usb";  /* 结构抄自 M4 模板同名项 */
	};

	ps_atc2_cio_pcie: power-controller@4f8 {
		compatible = "apple,t8142-pmgr-pwrstate", "apple,t8103-pmgr-pwrstate";
		reg = <0x4f8 4>;
		#power-domain-cells = <0>;
		#reset-cells = <0>;
		label = "atc2_cio_pcie";  /* 结构抄自 M4 模板同名项 */
	};

	ps_atc2_cio_usb: power-controller@500 {
		compatible = "apple,t8142-pmgr-pwrstate", "apple,t8103-pmgr-pwrstate";
		reg = <0x500 4>;
		#power-domain-cells = <0>;
		#reset-cells = <0>;
		label = "atc2_cio_usb";  /* 结构抄自 M4 模板同名项 */
	};

	ps_atc3_cio_pcie: power-controller@508 {
		compatible = "apple,t8142-pmgr-pwrstate", "apple,t8103-pmgr-pwrstate";
		reg = <0x508 4>;
		#power-domain-cells = <0>;
		#reset-cells = <0>;
		label = "atc3_cio_pcie";  /* 结构抄自 M4 模板同名项 */
	};

	ps_atc3_cio_usb: power-controller@510 {
		compatible = "apple,t8142-pmgr-pwrstate", "apple,t8103-pmgr-pwrstate";
		reg = <0x510 4>;
		#power-domain-cells = <0>;
		#reset-cells = <0>;
		label = "atc3_cio_usb";  /* 结构抄自 M4 模板同名项 */
	};

	/* ⚠️ M4 模板里没有同名项 —— 下面属性是猜的,需确认 */
	ps_sys_gp_ocla: power-controller@518 {
		compatible = "apple,t8142-pmgr-pwrstate", "apple,t8103-pmgr-pwrstate";
		reg = <0x518 4>;
		#power-domain-cells = <0>;
		#reset-cells = <0>;
		label = "sys_gp_ocla";
	};

	ps_apcie_sys_st: power-controller@520 {
		compatible = "apple,t8142-pmgr-pwrstate", "apple,t8103-pmgr-pwrstate";
		reg = <0x520 4>;
		#power-domain-cells = <0>;
		#reset-cells = <0>;
		label = "apcie_sys_st";  /* 结构抄自 M4 模板同名项 */
	};

	ps_apcie_phy_sw: power-controller@560 {
		compatible = "apple,t8142-pmgr-pwrstate", "apple,t8103-pmgr-pwrstate";
		reg = <0x560 4>;
		#power-domain-cells = <0>;
		#reset-cells = <0>;
		label = "apcie_phy_sw";  /* 结构抄自 M4 模板同名项 */
	};

	/* ⚠️ M4 模板里没有同名项 —— 下面属性是猜的,需确认 */
	ps_sys_st_ocla: power-controller@568 {
		compatible = "apple,t8142-pmgr-pwrstate", "apple,t8103-pmgr-pwrstate";
		reg = <0x568 4>;
		#power-domain-cells = <0>;
		#reset-cells = <0>;
		label = "sys_st_ocla";
	};

	/* ⚠️ M4 模板里没有同名项 —— 下面属性是猜的,需确认 */
	ps_st0_aus5_aon: power-controller@578 {
		compatible = "apple,t8142-pmgr-pwrstate", "apple,t8103-pmgr-pwrstate";
		reg = <0x578 4>;
		#power-domain-cells = <0>;
		#reset-cells = <0>;
		label = "st0_aus5_aon";
	};

	/* ⚠️ M4 模板里没有同名项 —— 下面属性是猜的,需确认 */
	ps_st0_aus5: power-controller@580 {
		compatible = "apple,t8142-pmgr-pwrstate", "apple,t8103-pmgr-pwrstate";
		reg = <0x580 4>;
		#power-domain-cells = <0>;
		#reset-cells = <0>;
		label = "st0_aus5";
	};

	ps_pmp: power-controller@598 {
		compatible = "apple,t8142-pmgr-pwrstate", "apple,t8103-pmgr-pwrstate";
		reg = <0x598 4>;
		#power-domain-cells = <0>;
		#reset-cells = <0>;
		label = "pmp";  /* 结构抄自 M4 模板同名项 */
		apple,always-on; /* Core device */
	};

	ps_pms_sram: power-controller@5a0 {
		compatible = "apple,t8142-pmgr-pwrstate", "apple,t8103-pmgr-pwrstate";
		reg = <0x5a0 4>;
		#power-domain-cells = <0>;
		#reset-cells = <0>;
		label = "pms_sram";  /* 结构抄自 M4 模板同名项 */
		apple,always-on; /* Core device */
	};

	ps_sep: power-controller@c00 {
		compatible = "apple,t8142-pmgr-pwrstate", "apple,t8103-pmgr-pwrstate";
		reg = <0xc00 4>;
		#power-domain-cells = <0>;
		#reset-cells = <0>;
		label = "sep";  /* 结构抄自 M4 模板同名项 */
		apple,always-on; /* Core device */
	};

	ps_venc_dma: power-controller@8000 {
		compatible = "apple,t8142-pmgr-pwrstate", "apple,t8103-pmgr-pwrstate";
		reg = <0x8000 4>;
		#power-domain-cells = <0>;
		#reset-cells = <0>;
		label = "venc_dma";  /* 结构抄自 M4 模板同名项 */
	};

	ps_venc_pipe4: power-controller@8008 {
		compatible = "apple,t8142-pmgr-pwrstate", "apple,t8103-pmgr-pwrstate";
		reg = <0x8008 4>;
		#power-domain-cells = <0>;
		#reset-cells = <0>;
		label = "venc_pipe4";  /* 结构抄自 M4 模板同名项 */
	};

	ps_venc_pipe5: power-controller@8010 {
		compatible = "apple,t8142-pmgr-pwrstate", "apple,t8103-pmgr-pwrstate";
		reg = <0x8010 4>;
		#power-domain-cells = <0>;
		#reset-cells = <0>;
		label = "venc_pipe5";  /* 结构抄自 M4 模板同名项 */
	};

	ps_venc_me0: power-controller@8018 {
		compatible = "apple,t8142-pmgr-pwrstate", "apple,t8103-pmgr-pwrstate";
		reg = <0x8018 4>;
		#power-domain-cells = <0>;
		#reset-cells = <0>;
		label = "venc_me0";  /* 结构抄自 M4 模板同名项 */
	};

	ps_venc_me1: power-controller@8020 {
		compatible = "apple,t8142-pmgr-pwrstate", "apple,t8103-pmgr-pwrstate";
		reg = <0x8020 4>;
		#power-domain-cells = <0>;
		#reset-cells = <0>;
		label = "venc_me1";  /* 结构抄自 M4 模板同名项 */
	};

	ps_ane_cpu: power-controller@c000 {
		compatible = "apple,t8142-pmgr-pwrstate", "apple,t8103-pmgr-pwrstate";
		reg = <0xc000 4>;
		#power-domain-cells = <0>;
		#reset-cells = <0>;
		label = "ane_cpu";  /* 结构抄自 M4 模板同名项 */
	};

	/* ⚠️ M4 模板里没有同名项 —— 下面属性是猜的,需确认 */
	ps_ane_tdbase: power-controller@c008 {
		compatible = "apple,t8142-pmgr-pwrstate", "apple,t8103-pmgr-pwrstate";
		reg = <0xc008 4>;
		#power-domain-cells = <0>;
		#reset-cells = <0>;
		label = "ane_tdbase";
	};

	ps_ane_mpm: power-controller@c010 {
		compatible = "apple,t8142-pmgr-pwrstate", "apple,t8103-pmgr-pwrstate";
		reg = <0xc010 4>;
		#power-domain-cells = <0>;
		#reset-cells = <0>;
		label = "ane_mpm";  /* 结构抄自 M4 模板同名项 */
	};

	ps_disp_cpu: power-controller@10000 {
		compatible = "apple,t8142-pmgr-pwrstate", "apple,t8103-pmgr-pwrstate";
		reg = <0x10000 4>;
		#power-domain-cells = <0>;
		#reset-cells = <0>;
		label = "disp_cpu";  /* 结构抄自 M4 模板同名项 */
	};

	/* ⚠️ M4 模板里没有同名项 —— 下面属性是猜的,需确认 */
	ps_disp_adma: power-controller@10068 {
		compatible = "apple,t8142-pmgr-pwrstate", "apple,t8103-pmgr-pwrstate";
		reg = <0x10068 4>;
		#power-domain-cells = <0>;
		#reset-cells = <0>;
		label = "disp_adma";
	};

};

/*
 * ====== 未写出:偏移在非虚拟域里仍不唯一(6 条)======
 *
 * 绝对地址 = base(group) + offset,base 来自 pmgr 的 ps-groups × reg。
 * 这几条的 (group, offset) 不同但 offset 相同,而 DT 的节点名单元地址
 * 用的是 offset(M4 的写法),会撞车。等定清 pmgr 的 ranges 怎么表达多基址再说。
 * 格式: offset  group  id  名字
 *
 *  0x00000  g=0  id=1     ECPU_0
 *  0x00000  g=2  id=512   GPX
 *  0x00058  g=1  id=199   DEBUG_GATED
 *  0x00058  g=0  id=12    PCPM
 *  0x00110  g=2  id=514   GFX
 *  0x00110  g=0  id=14    MSG
 */

/*
 * ====== 虚拟域(flags 带 0x10),本文件不处理(0 条)======
 *
 * 这些没有真实寄存器,是 PMGR 合成的状态域。是否需要在 DTS 里表达、
 * 以及怎么表达,未知 —— 上游 M4 的 dtsi 里也没有对应写法可参考。
 * 格式: offset  group  id  名字
 *
 */
